AUTOSAR XML (schema 314)
package /ComponentType
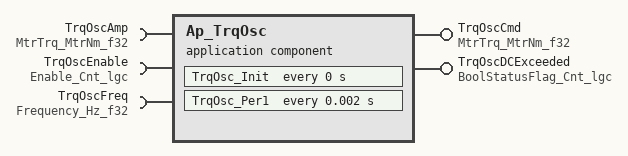
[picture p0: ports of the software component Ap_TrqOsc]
  application software component type Ap_TrqOsc
    provide port TrqOscCmd: unqueued-sender-com-spec{data-element=MtrNm_f32, can-invalidate=false, init-value=D_ZERO_ULS_F32}, provided-interface=MtrTrq_MtrNm_f32
    provide port TrqOscDCExceeded: unqueued-sender-com-spec{data-element=Cnt_lgc, can-invalidate=false, init-value=D_FALSE_CNT_LGC}, provided-interface=BoolStatusFlag_Cnt_lgc
    require port TrqOscAmp: unqueued-receiver-com-spec{data-element=MtrNm_f32, init-value=D_ZERO_ULS_F32}, required-interface=MtrTrq_MtrNm_f32
    require port TrqOscEnable: unqueued-receiver-com-spec{data-element=Cnt_lgc, init-value=D_FALSE_CNT_LGC}, required-interface=Enable_Cnt_lgc
    require port TrqOscFreq: unqueued-receiver-com-spec{data-element=Hz_f32, init-value=D_ZERO_ULS_F32}, required-interface=Frequency_Hz_f32
  internal behavior Ap_TrqOsc_InternalBehavior: component=Ap_TrqOsc
    timing event TrqOsc_InitEvent: start-on-event=TrqOsc_Init, period=0
    timing event TMT_TrqOsc_Per1: start-on-event=TrqOsc_Per1, period=0.002
    port-api-options:
      enable-take-address=false, indirect-api=false, port=TrqOscAmp
      enable-take-address=false, indirect-api=false, port=TrqOscCmd
      enable-take-address=false, indirect-api=false, port=TrqOscDCExceeded
      enable-take-address=false, indirect-api=false, port=TrqOscEnable
      enable-take-address=false, indirect-api=false, port=TrqOscFreq
    runnable TrqOsc_Init
    runnable TrqOsc_Per1
      data read access READ_TrqOscAmp_MtrNm_f32: data-element=TrqOscAmp.MtrNm_f32
      data read access READ_TrqOscEnable_Cnt_lgc: data-element=TrqOscEnable.Cnt_lgc
      data read access READ_TrqOscFreq_Hz_f32: data-element=TrqOscFreq.Hz_f32
      data write access WRITE_TrqOscCmd_MtrNm_f32: data-element=TrqOscCmd.MtrNm_f32
      data write access WRITE_TrqOscDCExceeded_Cnt_lgc: data-element=TrqOscDCExceeded.Cnt_lgc
  swc implementation Ap_TrqOsc_Implementation: behavior=Ap_TrqOsc_InternalBehavior
    code-descriptors:
      code Code: type=SRC
